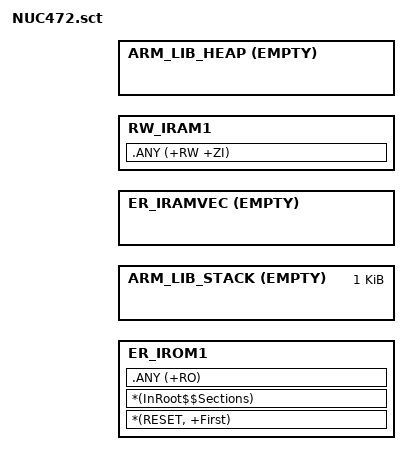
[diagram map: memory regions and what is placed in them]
#! armcc -E

/* Device specific values */
/* Tools provide -DMBED_ROM_START=0x0 -DMBED_ROM_SIZE=0x80000 -DMBED_RAM_START=0x20000000 -DMBED_RAM_SIZE=0x10000 */
/* Vectors in RAM */
#define VECTORS     (16 + 142)   /* This value must match NVIC_NUM_VECTORS */

/* Common - Do not change */

#if !defined(MBED_APP_START)
  #define MBED_APP_START  MBED_ROM_START
#endif

#if !defined(MBED_APP_SIZE)
  #define MBED_APP_SIZE  MBED_ROM_SIZE
#endif

#if !defined(MBED_BOOT_STACK_SIZE)
  #define MBED_BOOT_STACK_SIZE  0x400
#endif

/* Round up VECTORS_SIZE to 8 bytes */
#define VECTORS_SIZE (((VECTORS * 4) + 7) AND ~7)

LR_IROM1  MBED_APP_START  MBED_APP_SIZE  {
  ER_IROM1  MBED_APP_START  MBED_APP_SIZE  {  ; load address = execution address
   *(RESET, +First)
   *(InRoot$$Sections)
   .ANY (+RO)
  }

  ARM_LIB_STACK  MBED_RAM_START  EMPTY  MBED_BOOT_STACK_SIZE {
  }

  /* VTOR[TBLOFF] alignment requires:
   *
   * 1. Minumum 32-word
   * 2. Rounding up to the next power of two of table size
   */
  ER_IRAMVEC  AlignExpr(+0, 1024)  EMPTY  VECTORS_SIZE  {  ; Reserve for vectors
  }

  RW_IRAM1  AlignExpr(+0, 16)  {  ; 16 byte-aligned
   .ANY (+RW +ZI)
  }
  
  ARM_LIB_HEAP  AlignExpr(+0, 16)  EMPTY  (MBED_RAM_START + MBED_RAM_SIZE - AlignExpr(ImageLimit(RW_IRAM1), 16))  {
  }
}
ScatterAssert(LoadLimit(LR_IROM1) <= (MBED_APP_START + MBED_APP_SIZE))    ; 512 KB APROM
ScatterAssert(ImageLimit(RW_IRAM1) <= (MBED_RAM_START + MBED_RAM_SIZE))   ; 64 KB SRAM (internal)
